# MSP430FR2433 register map
Vendor: msp430gen; File version: v0.4.0-29-g702f6f3-dirty
Registers are 16-bit, read-write, reset 0x0 unless marked. A register's access mark holds for its fields unless they carry their own. Offsets are from the block's base; lines under a group give offsets from that group; [hi:lo] are bit positions; {n}, {i} and the like mark numbered series; 'fields as' and 'values as' point back to an identical list; <NAME> marks a mode.

## Memory map
0x00000100 SFR — SFR Special Function Registers
0x00000120 PMM — PMM Power Management System
0x00000140 SYS — SYS System Module
0x00000180 CS — CS Clock System
0x000001A0 FRCTL
0x000001C0 CRC
0x000001CC WDT_A
0x00000200 P1 — Port 1
0x00000200 P2 — Port 2
0x00000220 P3 — Port 3
0x00000300 RTC
0x00000380 TA0
0x000003C0 TA1
0x00000400 TA2
0x00000440 TA3
0x000004C0 MPY32
0x00000500 E_USCI_A0
0x00000520 E_USCI_A1
0x00000540 E_USCI_B0
0x00000660 BAKMEM
0x00000700 ADC
0x00001A00 TLV size 0x100 — Device descriptors (TLV)
0x0000FF80 _INTERRUPTS

## Interrupts
41 PORT2 (_INTERRUPTS) — 0xFFDA Port 2
42 PORT1 (_INTERRUPTS) — 0xFFDC Port 1
43 ADC (_INTERRUPTS) — 0xFFDE ADC
44 USCI_B0 (_INTERRUPTS) — 0xFFE0 USCI B0 Receive/Transmit
45 USCI_A1 (_INTERRUPTS) — 0xFFE2 USCI A1 Receive/Transmit
46 USCI_A0 (_INTERRUPTS) — 0xFFE4 USCI A0 Receive/Transmit
47 WDT (_INTERRUPTS) — 0xFFE6 Watchdog Timer
48 RTC (_INTERRUPTS) — 0xFFE8 RTC
49 TIMER3_A1 (_INTERRUPTS) — 0xFFEA Timer3_A2 CC1, TA
50 TIMER3_A0 (_INTERRUPTS) — 0xFFEC Timer3_A2 CC0
51 TIMER2_A1 (_INTERRUPTS) — 0xFFEE Timer2_A2 CC1, TA
52 TIMER2_A0 (_INTERRUPTS) — 0xFFF0 Timer2_A2 CC0
53 TIMER1_A1 (_INTERRUPTS) — 0xFFF2 Timer1_A3 CC1-2, TA
54 TIMER1_A0 (_INTERRUPTS) — 0xFFF4 Timer1_A3 CC0
55 TIMER0_A1 (_INTERRUPTS) — 0xFFF6 Timer0_A3 CC1-2, TA
56 TIMER0_A0 (_INTERRUPTS) — 0xFFE8 Timer0_A3 CC0
57 UNMI (_INTERRUPTS) — 0xFFFA User Non-maskable
58 SYSNMI (_INTERRUPTS) — 0xFFFC System Non-maskable

## P3 — Port 3
Base 0x00000220
0x00 P3IN 8-bit — Port 3 Input
  [7:0] P3IN — P3IN0
0x02 P3OUT 8-bit — Port 3 Output
  [7:0] P3OUT — P3OUT0
0x04 P3DIR 8-bit — Port 3 Direction
  [7:0] P3DIR — P3DIR0
0x06 P3REN 8-bit — Port 3 Resistor Enable
  [7:0] P3REN — P3REN0
0x0A P3SEL0 8-bit — Port 3 Selection0
  [7:0] P3SEL0 — P3SEL0_0
0x0C P3SEL1 8-bit — Port 3 Selection1
  [7:0] P3SEL1 — P3SEL1_0
0x16 P3SELC 8-bit — Port 3 Complement Select register

## SFR — SFR Special Function Registers
Base 0x00000100
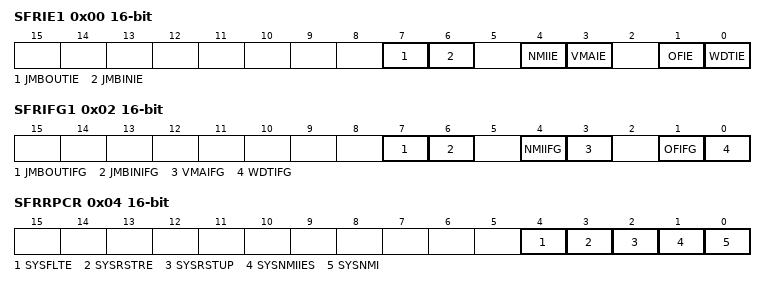
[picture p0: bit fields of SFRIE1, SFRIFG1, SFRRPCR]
0x00 SFRIE1 — Interrupt Enable 1
  [7] JMBOUTIE — JTAG Mail Box output Interrupt Enable
  [6] JMBINIE — JTAG Mail Box input Interrupt Enable
  [4] NMIIE — NMI Interrupt Enable
  [3] VMAIE — Vacant Memory Interrupt Enable
  [1] OFIE — Osc Fault Enable
  [0] WDTIE — WDT Interrupt Enable
0x02 SFRIFG1 — Interrupt Flag 1
  [7] JMBOUTIFG — JTAG Mail Box output Interrupt Flag
  [6] JMBINIFG — JTAG Mail Box input Interrupt Flag
  [4] NMIIFG — NMI Interrupt Flag
  [3] VMAIFG — Vacant Memory Interrupt Flag
  [1] OFIFG — Osc Fault Flag
    0=No interrupt pending; 1=Interrupt pending
  [0] WDTIFG — WDT Interrupt Flag
0x04 SFRRPCR — RESET Pin Control Register
  [4] SYSFLTE — Reset pin filter enable
    0=DISABLED (Reset pin filter disabled); 1=ENABLED (Reset pin filter enabled)
  [3] SYSRSTRE — RESET Pin Resistor enable
    0=DISABLE (Pullup or pulldown resistor at the RST/NMI pin is disabled); 1=ENABLE (Pullup or pulldown resistor at the RST/NMI pin is enabled)
  [2] SYSRSTUP — RESET Pin pull down/up select
    0=PULLDOWN (Pulldown is selected); 1=PULLUP (Pullup is selected)
  [1] SYSNMIIES — NMI edge select
    0=RISING (NMI on rising edge); 1=FALLING (NMI on falling edge)
  [0] SYSNMI — NMI select
    0=RESET (Reset function); 1=NMI (NMI function)

## PMM — PMM Power Management System
Base 0x00000120
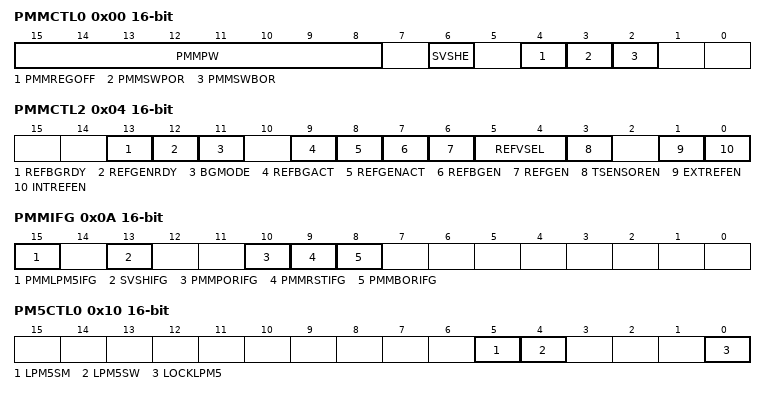
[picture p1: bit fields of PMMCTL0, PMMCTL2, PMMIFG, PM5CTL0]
0x00 PMMCTL0 — PMM Control 0
  [15:8] PMMPW — PMM Password
    on read: 150=PASSWORD (Values always reads from the PMMCTL0 register) | on write: 165=PASSWORD (Values which must be written to the PMMCTL0 register)
  [6] SVSHE — SVS high side enable
    0=DISABLED (High-side SVS (SVSH) is disabled in LPM2, LPM3, LPM4, LPM3.5, and LPM4.5. SVSH is always enabled in active mode, LPM0, and LPM1.); 1=ENABLED (SVSH is always enabled.)
  [4] PMMREGOFF — PMM Turn Regulator off
  [3] PMMSWPOR — PMM Software POR
  [2] PMMSWBOR — PMM Software BOR
0x01 PMMCTL0_H 8-bit (alternate view of PMMCTL0) — Power Management Module Control Register 0, upper byte
  [7:0] PMMPW — PMM password
    on read: 150=PASSWORD (Value always read from the PMM password) | on write: 0=LOCK (Locks the PMM registers again); 165=PASSWORD (Unlocks the PMM registers)
0x02 PMMCTL1 — PMM Control 1
0x04 PMMCTL2 — PMM Control 2
  [13] REFBGRDY — REF Reference bandgap ready
  [12] REFGENRDY — REF Reference generator ready
  [11] BGMODE — REF Bandgap mode
  [9] REFBGACT — REF Reference bandgap active
  [8] REFGENACT — REF Reference generator active
  [7] REFBGEN — Bandgap and bandgap buffer trigger. If written with a 1, the generation of the buffered bandgap voltage is started. When the bandgap buffer voltage request is set, this bit is cleared by hardware or writing 0.
  [6] REFGEN — Reference generator trigger. If written with a 1, the generation of the variable reference voltage is started. When the reference voltage request is set, this bit is cleared by hardware or writing 0.
  [5:4] REFVSEL — Internal reference voltage level select. 00b = 1.5V, 01b = 2.0V, 10b = 2.5V
    0=V1_5 (1.5 V)
  [3] TSENSOREN — Temperature Sensor Enable
  [1] EXTREFEN — External Reference output Enable
  [0] INTREFEN — Internal Reference Enable
0x0A PMMIFG — PMM Interrupt Flag
  [15] PMMLPM5IFG — LPM5 indication Flag
  [13] SVSHIFG — SVS low side interrupt flag
  [10] PMMPORIFG — PMM Software POR interrupt flag
  [9] PMMRSTIFG — PMM RESET pin interrupt flag
  [8] PMMBORIFG — PMM Software BOR interrupt flag
0x0E PMMIE — PMM Interrupt Enable
0x10 PM5CTL0 — PMM Power Mode 5 Control Register 0
  [5] LPM5SM — Manual mode for LPM3.5 switch
    0=AUTOMATIC (Automatic mode. The LPM3.5 switch is fully handled by the circuitry during mode switch.); 1=MANUAL (Manual mode. The LPM3.5 switch is specified by LPM5SW bit setting in software.)
  [4] LPM5SW — LPMx.5 switch dis/connected
    0=DISCONNECTED (LPMx.5 switch disconnected); 1=CONNECTED (LPMx.5 switch connected)
  [0] LOCKLPM5 — Lock I/O pin configuration upon entry/exit to/from LPM5
